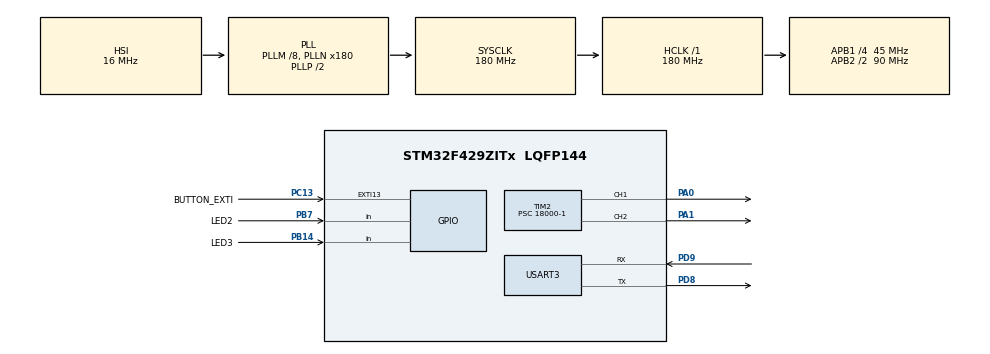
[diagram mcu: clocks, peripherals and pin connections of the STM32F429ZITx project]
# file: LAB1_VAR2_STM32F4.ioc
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Dma.Request0=USART3_TX
Dma.Request1=USART3_RX
Dma.USART3_RX.1.Direction=DMA_PERIPH_TO_MEMORY
Dma.USART3_RX.1.FIFOMode=DMA_FIFOMODE_DISABLE
Dma.USART3_RX.1.Instance=DMA1_Stream1
Dma.USART3_RX.1.MemDataAlignment=DMA_MDATAALIGN_BYTE
Dma.USART3_RX.1.MemInc=DMA_MINC_ENABLE
Dma.USART3_RX.1.Mode=DMA_NORMAL
Dma.USART3_RX.1.PeriphDataAlignment=DMA_PDATAALIGN_BYTE
Dma.USART3_RX.1.PeriphInc=DMA_PINC_DISABLE
Dma.USART3_RX.1.Priority=DMA_PRIORITY_LOW
Dma.USART3_TX.0.Direction=DMA_MEMORY_TO_PERIPH
Dma.USART3_TX.0.FIFOMode=DMA_FIFOMODE_DISABLE
Dma.USART3_TX.0.Instance=DMA1_Stream3
Dma.USART3_TX.0.MemDataAlignment=DMA_MDATAALIGN_BYTE
Dma.USART3_TX.0.MemInc=DMA_MINC_ENABLE
Dma.USART3_TX.0.Mode=DMA_NORMAL
Dma.USART3_TX.0.PeriphDataAlignment=DMA_PDATAALIGN_BYTE
Dma.USART3_TX.0.PeriphInc=DMA_PINC_DISABLE
Dma.USART3_TX.0.Priority=DMA_PRIORITY_LOW
FREERTOS.Tasks01=defaultTask,0,128,StartDefaultTask,Default,NULL,Static,defaultTaskBuffer,defaultTaskControlBlock;LedStateTask,-2,256,StartLedStateTask,Default,NULL,Static,LedStateTaskBuffer,LedStateTaskControlBlock;ReadBtnTask,-2,128,StartReadBtnTask,Default,NULL,Static,ReadBtnTaskBuffer,ReadBtnTaskControlBlock;USART_Task,-2,512,StartUSART_Task,Default,NULL,Static,USART_TaskBuffer,USART_TaskControlBlock
Mcu.Family=STM32F4
Mcu.Name=STM32F429ZITx
Mcu.Package=LQFP144
NVIC.DMA1_Stream1_IRQn=true\:5\:0\:false\:false\:true\:true\:false\:true\:true
NVIC.DMA1_Stream3_IRQn=true\:5\:0\:false\:false\:true\:true\:false\:true\:true
NVIC.EXTI15_10_IRQn=true\:5\:0\:false\:false\:true\:true\:true\:true\:true
NVIC.PriorityGroup=NVIC_PRIORITYGROUP_4
NVIC.TIM1_UP_TIM10_IRQn=true\:5\:0\:false\:false\:true\:true\:true\:true\:true
NVIC.TIM2_IRQn=true\:5\:0\:false\:false\:true\:true\:true\:true\:true
NVIC.TIM6_DAC_IRQn=true\:15\:0\:false\:false\:true\:false\:false\:true\:true
NVIC.TimeBase=TIM6_DAC_IRQn
NVIC.TimeBaseIP=TIM6
NVIC.USART3_IRQn=true\:5\:0\:false\:false\:true\:true\:true\:true\:true
PA0/WKUP.Signal=S_TIM2_CH1_ETR
PA1.Signal=S_TIM2_CH2
PA13.Mode=Serial_Wire
PA13.Signal=SYS_JTMS-SWDIO
PA14.Mode=Serial_Wire
PA14.Signal=SYS_JTCK-SWCLK
PB14.GPIO_Label=LED3
PB14.GPIO_PuPd=GPIO_PULLDOWN
PB14.Signal=GPIO_Input
PB7.GPIO_Label=LED2
PB7.GPIO_PuPd=GPIO_PULLDOWN
PB7.Signal=GPIO_Input
PC13.GPIO_Label=BUTTON_EXTI
PC13.GPIO_ModeDefaultEXTI=GPIO_MODE_IT_RISING
PC13.GPIO_PuPd=GPIO_PULLDOWN
PC13.Signal=GPXTI13
PD8.Mode=Asynchronous
PD8.Signal=USART3_TX
PD9.Mode=Asynchronous
PD9.Signal=USART3_RX
PH0/OSC_IN.Mode=HSE-External-Oscillator
PH0/OSC_IN.Signal=RCC_OSC_IN
PH1/OSC_OUT.Mode=HSE-External-Oscillator
PH1/OSC_OUT.Signal=RCC_OSC_OUT
ProjectManager.HeapSize=0x200
ProjectManager.StackSize=0x400
ProjectManager.TargetToolchain=STM32CubeIDE
RCC.48MHZClocksFreq_Value=90000000
RCC.AHBFreq_Value=180000000
RCC.APB1CLKDivider=RCC_HCLK_DIV4
RCC.APB1Freq_Value=45000000
RCC.APB1TimFreq_Value=90000000
RCC.APB2CLKDivider=RCC_HCLK_DIV2
RCC.APB2Freq_Value=90000000
RCC.APB2TimFreq_Value=180000000
RCC.CortexFreq_Value=180000000
RCC.HCLKFreq_Value=180000000
RCC.HSE_VALUE=25000000
RCC.HSI_VALUE=16000000
RCC.LSE_VALUE=32768
RCC.PLLM=8
RCC.PLLN=180
RCC.SYSCLKFreq_VALUE=180000000
RCC.SYSCLKSource=RCC_SYSCLKSOURCE_PLLCLK
RCC.VCOOutputFreq_Value=360000000
SH.S_TIM2_CH1_ETR.0=TIM2_CH1,PWM Generation1 CH1
SH.S_TIM2_CH2.0=TIM2_CH2,PWM Generation2 CH2
TIM1.Period=1000-1
TIM1.Prescaler=900-1
TIM2.Channel-PWM\ Generation1\ CH1=TIM_CHANNEL_1
TIM2.Channel-PWM\ Generation2\ CH2=TIM_CHANNEL_2
TIM2.Period=100-1
TIM2.Prescaler=18000-1
USART3.VirtualMode=VM_ASYNC
VP_FREERTOS_VS_CMSIS_V1.Mode=CMSIS_V1
VP_SYS_VS_tim6.Mode=TIM6
VP_TIM1_VS_ClockSourceINT.Mode=Internal
VP_TIM2_VS_ClockSourceINT.Mode=Internal
board=custom

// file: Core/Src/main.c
/* USER CODE BEGIN Header */
/**
 ******************************************************************************
 * @file           : main.c
 * @brief          : Main program body
 ******************************************************************************
 * @attention
 *
 * Copyright (c) 2022 STMicroelectronics.
 * All rights reserved.
 *
 * This software is licensed under terms that can be found in the LICENSE file
 * in the root directory of this software component.
 * If no LICENSE file comes with this software, it is provided AS-IS.
 *
 ******************************************************************************
 */
/* USER CODE END Header */
#include "main.h"
#include "cmsis_os.h"
#include "dma.h"
#include "tim.h"
#include "usart.h"
#include "gpio.h"

/* USER CODE BEGIN Includes */
#include "stdio.h"
#include "string.h"
#include "stdio.h"
#include <string.h>

/* USER CODE END Includes */

/* USER CODE BEGIN PV */

extern volatile uint8_t value;	//змінна в котру запи�?ують байт інформаціїї з терміналу

extern UART_HandleTypeDef huart3;
extern DMA_HandleTypeDef hdma_usart3_tx;
extern DMA_HandleTypeDef hdma_usart3_rx;

/* USER CODE END PV */

void SystemClock_Config(void);
void MX_FREERTOS_Init(void);

int main(void)
{

  /* MCU Configuration--------------------------------------------------------*/

  /* Reset of all peripherals, Initializes the Flash interface and the Systick. */
   HAL_Init();

  /* Configure the system clock */
  SystemClock_Config();

  /* Initialize all configured peripherals */
  MX_GPIO_Init();
  MX_DMA_Init();
  MX_TIM1_Init();
  MX_TIM2_Init();
  MX_USART3_UART_Init();
  /* USER CODE BEGIN 2 */

	setvbuf(stdin, NULL, _IONBF, 0); // определение нулевого буфера
	printf("PRINT BRIGHTNESS FOR LED In range from 0 to 100->>>>!\r\n");
	HAL_UART_Receive_IT(&huart3, &value, 1); //запу�?каем UART по прерыванию

	HAL_TIM_PWM_Start(&htim2, TIM_CHANNEL_1);
	HAL_TIM_PWM_Start(&htim2, TIM_CHANNEL_2);

  /* USER CODE END 2 */

  /* Call init function for freertos objects (in freertos.c) */
  MX_FREERTOS_Init();

  /* Start scheduler */
  osKernelStart();

  /* We should never get here as control is now taken by the scheduler */
  /* Infinite loop */
	while (1)
	{

	}
}

void SystemClock_Config(void)
{
  RCC_OscInitTypeDef RCC_OscInitStruct = {0};
  RCC_ClkInitTypeDef RCC_ClkInitStruct = {0};

  /** Configure the main internal regulator output voltage
  */
  __HAL_RCC_PWR_CLK_ENABLE();
  __HAL_PWR_VOLTAGESCALING_CONFIG(PWR_REGULATOR_VOLTAGE_SCALE1);

  /** Initializes the RCC Oscillators according to the specified parameters
  * in the RCC_OscInitTypeDef structure.
  */
  RCC_OscInitStruct.OscillatorType = RCC_OSCILLATORTYPE_HSI;
  RCC_OscInitStruct.HSIState = RCC_HSI_ON;
  RCC_OscInitStruct.HSICalibrationValue = RCC_HSICALIBRATION_DEFAULT;
  RCC_OscInitStruct.PLL.PLLState = RCC_PLL_ON;
  RCC_OscInitStruct.PLL.PLLSource = RCC_PLLSOURCE_HSI;
  RCC_OscInitStruct.PLL.PLLM = 8;
  RCC_OscInitStruct.PLL.PLLN = 180;
  RCC_OscInitStruct.PLL.PLLP = RCC_PLLP_DIV2;
  RCC_OscInitStruct.PLL.PLLQ = 4;
  if (HAL_RCC_OscConfig(&RCC_OscInitStruct) != HAL_OK)
  {
    Error_Handler();
  }

  /** Activate the Over-Drive mode
  */
  if (HAL_PWREx_EnableOverDrive() != HAL_OK)
  {
    Error_Handler();
  }

  /** Initializes the CPU, AHB and APB buses clocks
  */
  RCC_ClkInitStruct.ClockType = RCC_CLOCKTYPE_HCLK|RCC_CLOCKTYPE_SYSCLK
                              |RCC_CLOCKTYPE_PCLK1|RCC_CLOCKTYPE_PCLK2;
  RCC_ClkInitStruct.SYSCLKSource = RCC_SYSCLKSOURCE_PLLCLK;
  RCC_ClkInitStruct.AHBCLKDivider = RCC_SYSCLK_DIV1;
  RCC_ClkInitStruct.APB1CLKDivider = RCC_HCLK_DIV4;
  RCC_ClkInitStruct.APB2CLKDivider = RCC_HCLK_DIV2;

  if (HAL_RCC_ClockConfig(&RCC_ClkInitStruct, FLASH_LATENCY_5) != HAL_OK)
  {
    Error_Handler();
  }
}

void HAL_TIM_PeriodElapsedCallback(TIM_HandleTypeDef *htim)
{
  if (htim->Instance == TIM6) {
    HAL_IncTick();
  }
}

void Error_Handler(void)
{
	__disable_irq();
	while (1)
	{
	}
}
